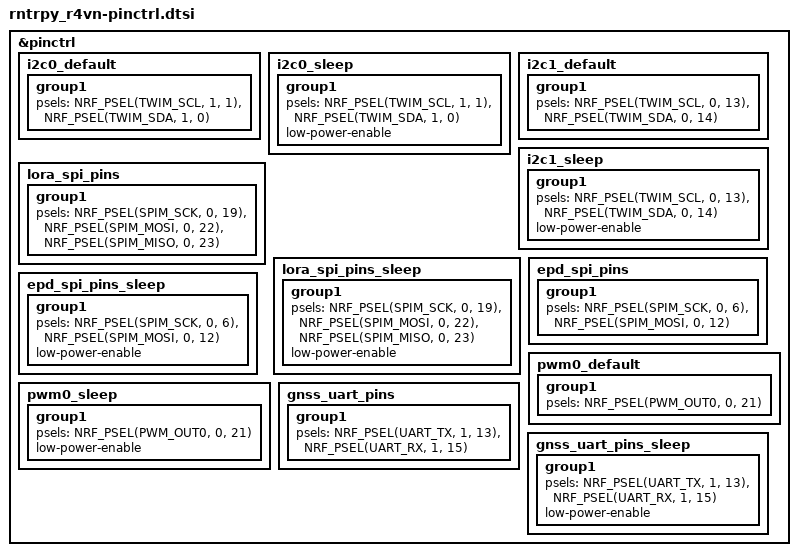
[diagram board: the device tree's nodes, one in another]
/*
 * Copyright (c) 2024 MASSDRIVER EI (massdriver.space)
 * SPDX-License-Identifier: Apache-2.0
 */

&pinctrl {
	i2c0_default: i2c0_default {
		group1 {
			psels = <NRF_PSEL(TWIM_SCL, 1, 1)>,
				<NRF_PSEL(TWIM_SDA, 1, 0)>;
		};
	};

	i2c0_sleep: i2c0_sleep {
		group1 {
			psels = <NRF_PSEL(TWIM_SCL, 1, 1)>,
				<NRF_PSEL(TWIM_SDA, 1, 0)>;
			low-power-enable;
		};
	};

	i2c1_default: i2c1_default {
		group1 {
			psels = <NRF_PSEL(TWIM_SCL, 0, 13)>,
				<NRF_PSEL(TWIM_SDA, 0, 14)>;
		};
	};

	i2c1_sleep: i2c1_sleep {
		group1 {
			psels = <NRF_PSEL(TWIM_SCL, 0, 13)>,
				<NRF_PSEL(TWIM_SDA, 0, 14)>;
			low-power-enable;
		};
	};

	lora_spi_pins: lora_spi_pins {
		group1 {
			psels = <NRF_PSEL(SPIM_SCK, 0, 19)>,
				<NRF_PSEL(SPIM_MOSI, 0, 22)>,
				<NRF_PSEL(SPIM_MISO, 0, 23)>;
		};
	};

	lora_spi_pins_sleep: lora_spi_pins_sleep {
		group1 {
			psels = <NRF_PSEL(SPIM_SCK, 0, 19)>,
				<NRF_PSEL(SPIM_MOSI, 0, 22)>,
				<NRF_PSEL(SPIM_MISO, 0, 23)>;
			low-power-enable;
		};
	};

	epd_spi_pins: epd_spi_pins {
		group1 {
			psels = <NRF_PSEL(SPIM_SCK, 0, 6)>,
				<NRF_PSEL(SPIM_MOSI, 0, 12)>;
		};
	};

	epd_spi_pins_sleep: epd_spi_pins_sleep {
		group1 {
			psels = <NRF_PSEL(SPIM_SCK, 0, 6)>,
				<NRF_PSEL(SPIM_MOSI, 0, 12)>;
			low-power-enable;
		};
	};

	/* E-paper frontlight, active high */
	pwm0_default: pwm0_default {
		group1 {
			psels = <NRF_PSEL(PWM_OUT0, 0, 21)>;
		};
	};

	pwm0_sleep: pwm0_sleep {
		group1 {
			psels = <NRF_PSEL(PWM_OUT0, 0, 21)>;
			low-power-enable;
		};
	};

	/*
	 * The GPIO map names these pins from the MAX-M10S side:
	 * P1.13 is the module's RX (our TX), P1.15 its TX (our RX).
	 */
	gnss_uart_pins: gnss_uart_pins {
		group1 {
			psels = <NRF_PSEL(UART_TX, 1, 13)>,
				<NRF_PSEL(UART_RX, 1, 15)>;
		};
	};

	gnss_uart_pins_sleep: gnss_uart_pins_sleep {
		group1 {
			psels = <NRF_PSEL(UART_TX, 1, 13)>,
				<NRF_PSEL(UART_RX, 1, 15)>;
			low-power-enable;
		};
	};
};
